# STM32F407 register map
File version: 1.7
CPU: CM4 r0p1, little endian, MPU, FPU, 4 interrupt priority bits
Registers are 32-bit, read-write, reset 0x0 unless marked. A register's access mark holds for its fields unless they carry their own. Offsets are from the block's base; [hi:lo] are bit positions; {n}, {i} and the like mark numbered series; 'fields as' and 'values as' point back to an identical list.

## SYSCFG — System configuration controller
Base 0x40013800
0x00 MEMRMP — memory remap register
  [1:0] MEM_MODE
    0=Main Flash memory mapped at 0x0000 0000; 1=System Flash memory mapped at 0x0000 0000; 2=FSMC Bank1 (NOR/PSRAM 1 and 2) mapped at 0x0000 0000; 3=Embedded SRAM mapped at 0x0000 0000
0x04 PMC — peripheral mode configuration register
  [23] MII_RMII_SEL — Ethernet PHY interface selection
    0=MII (MII interface is selected); 1=RMII_PHY (RMII PHY interface is selected)
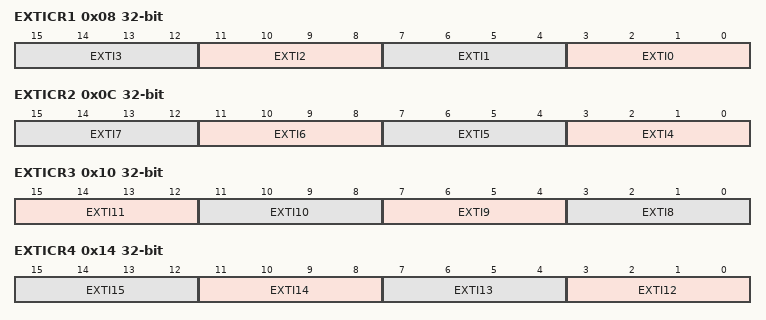
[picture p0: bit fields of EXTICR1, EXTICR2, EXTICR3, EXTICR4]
0x08 EXTICR1 — external interrupt configuration register 1
  [all] fields
    0=PA (Select PAx as the source input for the EXTIx external interrupt); 1=PB (Select PBx as the source input for the EXTIx external interrupt); 2=PC (Select PCx as the source input for the EXTIx external interrupt); 3=PD (Select PDx as the source input for the EXTIx external interrupt); 4=PE (Select PEx as the source input for the EXTIx external interrupt); 5=PF (Select PFx as the source input for the EXTIx external interrupt); 6=PG (Select PGx as the source input for the EXTIx external interrupt); 7=PH (Select PHx as the source input for the EXTIx external interrupt); 8=PI (Select PIx as the source input for the EXTIx external interrupt)
  [4n+3:4n] EXTI{n} (n=0..3) — EXTI x configuration (x = 0 to 3)
0x0C EXTICR2 — external interrupt configuration register 2
  [all] fields
    values as the fields of EXTICR1
  [4n-13:4n-16] EXTI{n} (n=4..7) — EXTI x configuration (x = 4 to 7)
0x10 EXTICR3 — external interrupt configuration register 3
  [all] fields
    values as the fields of EXTICR1
  [15:12] EXTI11 — EXTI x configuration (x = 8 to 11)
  [11:8] EXTI10
  [7:4] EXTI9 — EXTI x configuration (x = 8 to 11)
  [3:0] EXTI8 — EXTI x configuration (x = 8 to 11)
0x14 EXTICR4 — external interrupt configuration register 4
  [all] fields
    values as the fields of EXTICR1
  [4n-45:4n-48] EXTI{n} (n=12..15) — EXTI x configuration (x = 12 to 15)
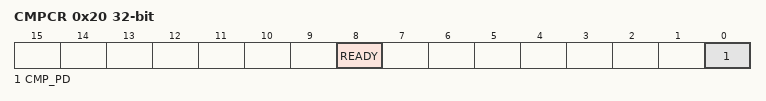
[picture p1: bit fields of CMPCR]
0x20 CMPCR ro — Compensation cell control register
  [8] READY
    0=NotReady (I/O compensation cell not ready); 1=Ready (I/O compensation cell ready)
  [0] CMP_PD rw — Compensation cell power-down
    0=PowerDown (I/O compensation cell power-down mode); 1=Enabled (I/O compensation cell enabled)

## PWR — Power control
Base 0x40007000
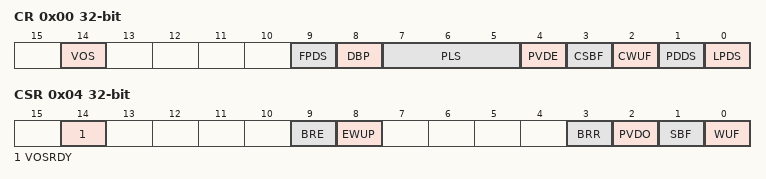
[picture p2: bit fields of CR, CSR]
0x00 CR — power control register
  [14] VOS — Regulator voltage scaling output selection
    0=Scale 2 mode; 1=Scale 1 mode (default value at reset)
  [9] FPDS — Flash power down in Stop mode
    0=Idle (Flash memory not in power-down when the device is in Stop mode); 1=PowerDown (Flash memory in power-down when the device is in Stop mode)
  [8] DBP — Disable backup domain write protection
    0=Protected (Access to RTC and RTC Backup registers and backup SRAM disabled); 1=Writable (Access to RTC and RTC Backup registers and backup SRAM enabled)
  [7:5] PLS — PVD level selection
  [4] PVDE — Power voltage detector enable
    0=Disabled (PVD disabled); 1=Enabled (PVD enabled)
  [3] CSBF — Clear standby flag
    on read: 0=Zero (This bit is always read as 0) | on write: 1=Clear the SBF Standby Flag
  [2] CWUF — Clear wakeup flag
    on read: 0=Zero (This bit is always read as 0) | on write: 1=Clear the WUPF Wakeup Flag **after 2 System clock cycles**
  [1] PDDS — Power down deepsleep
    0=Enter Stop mode when the CPU enters deepsleep. The regulator status depends on the LPDS bit; 1=Enter Standby mode when the CPU enters deepsleep
  [0] LPDS — Low-power deep sleep
    0=Main voltage regulator ON during Stop mode; 1=Low-power voltage regulator ON during Stop mode
0x04 CSR access per field — power control/status register
  [14] VOSRDY ro — Regulator voltage scaling output selection ready bit
    0=NotReady; 1=Ready
  [9] BRE rw — Backup regulator enable
    0=Disabled (Backup regulator disabled); 1=Enabled (Backup regulator enabled)
  [8] EWUP rw — Enable WKUP pin
    0=GPIO (WKUP1 pin is used for general purpose I/O. An event on the WKUP1 pin does not wakeup the device from Standby mode); 1=WakeUp (WKUP1 pin is used for wakeup from Standby mode and forced in input pull down configuration (rising edge or falling on WKUP pin wakes-up the system from Standby mode))
  [3] BRR ro — Backup regulator ready
    0=NotReady (Backup Regulator not ready); 1=Ready (Backup Regulator ready)
  [2] PVDO ro — PVD output
    0=Higher (Vdd is higher than the PVD threshold selected with the PLS[2:0] bits); 1=Lower (Vdd is lower than the PVD threshold selected with the PLS[2:0] bits)
  [1] SBF ro — Standby flag
    0=InStandby (Device has not been in Standby mode); 1=NotInStandby (Device has been in Standby mode)
  [0] WUF ro — Wakeup flag
    0=NotOccurred (No wakeup event occurred); 1=Occurred (A wakeup event was received from the WKUP pin or from the RTC alarm (Alarm A or Alarm B), RTC Tamper event, RTC TimeStamp event or RTC Wakeup))
